# NANO100BN_v1 register map
File version: 1.0
Registers are 32-bit, read-write, reset 0x0 unless marked. A register's access mark holds for its fields unless they carry their own. Offsets are from the block's base; [hi:lo] are bit positions; {n}, {i} and the like mark numbered series; 'fields as' and 'values as' point back to an identical list.

## TMR0 — TMR Register Map
Base 0x40010000
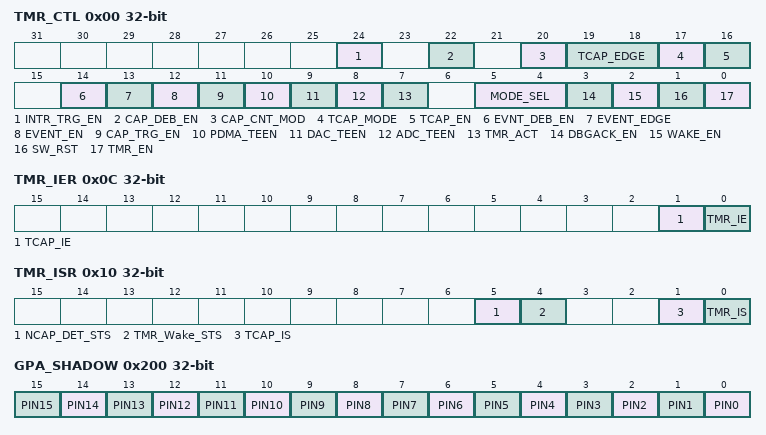
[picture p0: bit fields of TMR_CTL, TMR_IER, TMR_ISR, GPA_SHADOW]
0x00 TMR_CTL — Timer x Control Register
  [24] INTR_TRG_EN — Inter-Timer Trigger Mode Enable. This bit controls if Inter-timer Trigger mode is enabled. If Inter-timer Trigger mode is enabled, the TMRx will be in counter mode and counting with external Clock Source or event. And, TMRx+1 will be in trigger-counting mode of capture function. Note: For TMRx+1_CTL, this bit is ignored and the read back value is always 1'b0.
    0=Inter-timer trigger mode Disabled; 1=Inter-timer trigger mode Enabled
  [22] CAP_DEB_EN — Tcapture Pin De-bounce Enable. When CAP_DEB_EN is set, the Tcapture pin de-bounce circuit will be enabled to eliminate the bouncing of the signal. In de-bounce circuit the Tcapture pin signal will be sampled 4 times by TMRx_CLK. Note: When TCAP_EN is enabled, enable this bit is recommended. And, while TCAP_EN is disabled, disable this bit is recommended to save power consumption.
    0=De-bounce circuit Disabled; 1=De-bounce circuit Enabled
  [20] CAP_CNT_MOD — Timer Capture Counting Mode Selection. This bit indicates the behavior of 24-bit up-counting timer while TCAP_EN is set to high. If this bit is 0, the free-counting mode, the behavior of 24-bit up-counting timer is defined by MODE_SEL field. When TCAP_EN is set, TCAP_MODE is 0, and the transition of Tcapture pin matches the TCAP_EDGE setting, the value of 24-bit up-counting timer will be saved into register TMRx_TCAPn. If this bit is 1, Trigger-counting mode, 24-bit up-counting timer will be not counting and keep its value at zero. When TCAP_EN is set, TCAP_MODE is 0, and once the transition of external pin matches the 1st transition of TCAP_EDGE setting, the 24-bit up-counting timer will start counting. And then if the transition of external pin matches the 2nd transition of TCAP_EDGE setting, the 24-bit up-counting timer will stop counting. And its value will be saved into register TMRx_TCAPn. Note: For TMRx+1_CTL, if INTR_TRG_EN is set, the CAP_CNT_MOD will be forced to high, the capture with Trigger-counting Timer mode.
    0=Capture with free-counting timer mode; 1=Capture with trigger-counting timer mode
  [19:18] TCAP_EDGE — Tcapture Pin Edge Detect Selection
  [17] TCAP_MODE — Tcapture Pin Function Mode Selection. This bit indicates if the transition on Tcapture pin is used as timer counter reset function or timer capture function. Note: For TMRx+1_CTL, if INTR_TRG_EN is set, the TCAP_MODE will be forced to low.
    0=The transition on Tcapture pin is used as timer capture function; 1=The transition on Tcapture pin is used as timer counter reset function
  [16] TCAP_EN — Tcapture Pin Functional Enable. This bit controls if the transition on Tcapture pin could be used as timer counter reset function or timer capture function. Note: For TMRx_CTL, if INTR_TRG_EN is set, the TCAP_EN will be forced to low and the Tcapture pin transition is ignored. Note: For TMRx+1_CTL, if INTR_TRG_EN is set, the TCAP_EN will be forced to high.
    0=The transition on Tcapture pin is ignored; 1=The transition on Tcapture pin will result in the capture or reset of 24-bit timer counter
  [14] EVNT_DEB_EN — External Event De-bounce Enable. When EVNT_DEB_EN is set, the external event pin de-bounce circuit will be enabled to eliminate the bouncing of the signal. In de-bounce circuit the external event pin will be sampled 4 times by TMRx_CLK. Note: When EVENT_EN is enabled, enable this bit is recommended. And, while EVENT_EN is disabled, disable this bit is recommended to save power consumption.
    0=De-bounce circuit Disabled; 1=De-bounce circuit Enabled
  [13] EVENT_EDGE — Event Counting Mode Edge Selection. This bit indicates which edge of external event pin enabling the timer to increase 1.
    0=A falling edge of external event enabling the timer to increase 1; 1=A rising edge of external event enabling the timer to increase 1
  [12] EVENT_EN — Event Counting Mode Enable. When EVENT_EN is set, the increase of 24-bit up-counting timer is controlled by external event pin. While the transition of external event pin matches the definition of EVENT_EDGE, the 24-bit up-counting timer increases by 1. Or, the 24-bit up-counting timer will keep its value unchanged.
    0=Timer counting is not controlled by external event pin; 1=Timer counting is controlled by external event pin
  [11] CAP_TRG_EN — TCAP_IS Trigger Mode Enable. This bit controls if the TMR_IS or TCAP_IS is used to trigger PDMA, DAC and ADC while TMR_IS or TCAP_IS is set. If this bit is low and TMR_IS is set, timer will generate an internal trigger event to PDMA, DAC or ADC while related trigger enable bit (PDMA_TEEN, DAC_TEEN or ADC_TEEN) is also set. If this bit is set high and TCAP_IS is set, timer will generate an internal trigger event to PDMA, DAC or ADC while related trigger enable bit (PDMA_TEEN, DAC_TEEN or ADC_TEEN) is also set.
    0=TMR_IS is used to trigger PDMA, DAC and ADC; 1=TCAP_IS is used to trigger PDMA, DAC and ADC
  [10] PDMA_TEEN — TMR_IS or TCAP_IS Trigger PDMA Enable. This bit controls if TMR_IS or TCAP_IS could trigger PDMA. When PDMA_TEEN is set, TMR_IS is set and the CAP_TRG_EN is low, the timer controller will generate an internal trigger event to PDMA controller. When PDMA_TEEN is set, TCAP_IS is set and the CAP_TRG_EN is high, the timer controller will generate an internal trigger event to PDMA controller.
    0=TMR_IS or TCAP_IS trigger PDMA Disabled; 1=TMR_IS or TCAP_IS trigger PDMA Enabled
  [9] DAC_TEEN — TMR_IS or TCAP_IS Trigger DAC Enable. This bit controls if TMR_IS or TCAP_IS could trigger DAC. When DAC_TEEN is set, TMR_IS is set and the CAP_TRG_EN is low, the timer controller will generate an internal trigger event to DAC controller. When DAC_TEEN is set, TCAP_IS is set and the CAP_TRG_EN is high, the timer controller will generate an internal trigger event to DAC controller.
    0=TMR_IS or TCAP_IS trigger DAC Disabled; 1=TMR_IS or TCAP_IS trigger DAC Enabled
  [8] ADC_TEEN — TMR_IS or TCAP_IS Trigger ADC Enable. This bit controls if TMR_IS or TCAP_IS could trigger ADC. When ADC_TEEN is set, TMR_IS is set and the CAP_TRG_EN is low, the timer controller will generate an internal trigger event to ADC controller. When ADC_TEEN is set, TCAP_IS is set and the CAP_TRG_EN is high, the timer controller will generate an internal trigger event to ADC controller.
    0=TMR_IS or TCAP_IS trigger ADC Disabled; 1=TMR_IS or TCAP_IS trigger ADC Enabled
  [7] TMR_ACT ro — Timer Active Status Bit (Read Only). This bit indicates the timer counter status of timer.
    0=Timer is not active; 1=Timer is in active
  [5:4] MODE_SEL — Timer Operating Mode Select
  [3] DBGACK_EN — ICE Debug Mode Acknowledge Ineffective Enable
    0=ICE debug mode acknowledgement effects TIMER counting and TIMER counter will be held while ICE debug mode acknowledged; 1=ICE debug mode acknowledgement is ineffective and TIMER counter will keep going no matter ICE debug mode acknowledged or not
  [2] WAKE_EN — Wake-up Enable. When WAKE_EN is set and the TMR_IS or TCAP_IS is set, the timer controller will generate a wake-up trigger event to CPU.
    0=Wake-up trigger event Disabled; 1=Wake-up trigger event Enabled
  [1] SW_RST — Software Reset. Set this bit will reset the timer counter, pre-scale counter and also force TMR_CTL [TMR_EN] to 0. Note: This bit will be auto cleared and takes at least 3 TMRx_CLK clock cycles.
    0=No effect; 1=Reset Timer's pre-scale counter, internal 24-bit up-counter and TMR_CTL [TMR_EN] bit
  [0] TMR_EN — Timer Counter Enable Bit
    0=Stops/Suspends counting; 1=Starts counting
0x04 TMR_PRECNT — Timer x Pre-Scale Counter Register
  [7:0] PRESCALE_CNT — Pre-scale Counter
0x08 TMR_CMPR — Timer x Compare Register
  [23:0] TMR_CMP — Timer Compared Value. TMR_CMP is a 24-bit compared register. When the internal 24-bit up-counter counts and its value is equal to TMR_CMP value, a Timer Interrupt is requested if the timer interrupt is enabled with TMR_IER [TMR_IE] is enabled. The TMR_CMP value defines the timer counting cycle time. Note1: Never write 0x0 or 0x1 in TMR_CMP, or the core will run into unknown state. Note2: No matter TMR_CTL [TMR_EN] is 0 or 1, whenever software write a new value into this register, TIMER will restart counting using this new value and abort previous count.
0x0C TMR_IER — Timer x Interrupt Enable Register
  [1] TCAP_IE — Timer Capture Function Interrupt Enable. Note: If timer external pin function interrupt is enabled, the timer asserts its interrupt signal when the TCAP_EN is set and the transition of external pin matches the TCAP_EDGE setting
    0=Timer External Pin Function Interrupt Disabled; 1=Timer External Pin Function Interrupt Enabled
  [0] TMR_IE — Timer Interrupt Enable. Note: If timer interrupt is enabled, the timer asserts its interrupt signal when the associated counter is equal to TMR_CMPR.
    0=Timer Interrupt Disabled; 1=Timer Interrupt Enabled
0x10 TMR_ISR — Timer x Interrupt Status Register
  [5] NCAP_DET_STS — New Capture Detected Status. This status is to indicate there is a new incoming capture event detected before CPU clearing the TCAP_IS status. If the above condition occurred, the Timer will keep register TMRx_CAP unchanged and drop the new capture value. This bit is also cleared to 0 while TCAP_IS is cleared.
    0=New incoming capture event didn't detect before CPU clearing TCAP_IS status; 1=New incoming capture event detected before CPU clearing TCAP_IS status
  [4] TMR_Wake_STS — Timer Wake-up Status. If timer causes CPU wakes up from power-down mode, this bit will be set to high. It must be cleared by software with a write 1 to this bit.
    0=Timer does not cause system wake-up; 1=Wakes system up from power-down mode by Timer timeout
  [1] TCAP_IS — Timer Capture Function Interrupt Status. This bit indicates the external pin function interrupt status of Timer. This bit is set by hardware when TCAP_EN is set high, and the transition of external pin matches the TCAP_EDGE setting. Write 1 to clear this bit to zero. If this bit is active and TCAP_IE is enabled, Timer will trigger an interrupt to CPU.
  [0] TMR_IS — Timer Interrupt Status. This bit indicates the interrupt status of Timer. This bit is set by hardware when the up counting value of internal 24-bit counter matches the timer compared value (TMR_CMPR). Write 1 to clear this bit to 0. If this bit is active and TMR_IE is enabled, Timer will trigger an interrupt to CPU.
0x14 TMR_DR ro — Timer x Data Register
  [23:0] TDR — Timer Data Register. User can read this register for internal 24-bit timer up-counter value.
0x18 TMR_TCAP ro — Timer x Capture Data Register
  [23:0] CAP — Timer Capture Data Register. When TCAP_EN is set, TCAP_MODE is 0, and the transition of external pin matches the TCAP_EDGE setting, the value of 24-bit up-counting timer will be saved into register TMRx_TCAP. User can read this register for the counter value.
0x200 GPA_SHADOW ro (reset mask 0xFFFF0000) — GPIO Port A Pin Value Shadow Register
  [n] PIN{n} (n=0..15) — GPIO Port [A/B/C/D/E/F] Pin Values. The value read from each of these bit reflects the actual status of the respective GPI/O pin. These registers are shadow registers of GPIOx_PIN register. Note: For GPF_SHADOW, bits [15:9] are reserved.
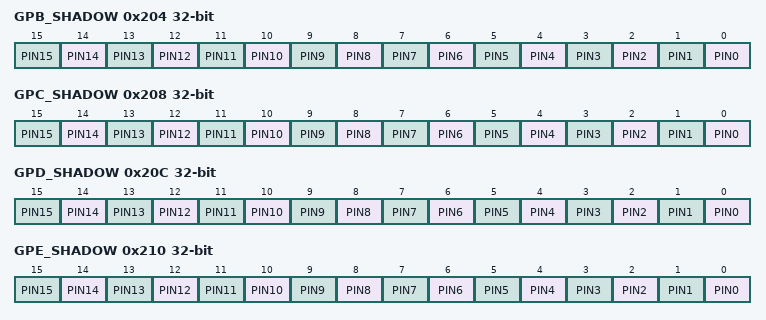
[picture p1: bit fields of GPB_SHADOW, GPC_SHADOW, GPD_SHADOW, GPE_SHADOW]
0x204 GPB_SHADOW ro (reset mask 0xFFFF0000) — GPIO Port B Pin Value Shadow Register
  fields as GPA_SHADOW
0x208 GPC_SHADOW ro (reset mask 0xFFFF0000) — GPIO Port C Pin Value Shadow Register
  fields as GPA_SHADOW
0x20C GPD_SHADOW ro (reset mask 0xFFFF0000) — GPIO Port D Pin Value Shadow Register
  fields as GPA_SHADOW
0x210 GPE_SHADOW ro (reset mask 0xFFFF0000) — GPIO Port E Pin Value Shadow Register
  fields as GPA_SHADOW
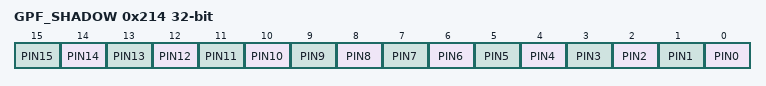
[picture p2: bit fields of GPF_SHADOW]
0x214 GPF_SHADOW ro (reset mask 0xFFFF0000) — GPIO Port F Pin Value Shadow Register
  fields as GPA_SHADOW

## TMR1 — TMR Register Map
Base 0x40010100
Registers as TMR0, without GPA_SHADOW, GPB_SHADOW, GPC_SHADOW, GPD_SHADOW, GPE_SHADOW, GPF_SHADOW.

## TMR2 — TMR Register Map
Base 0x40110000
Registers as TMR0, without GPA_SHADOW, GPB_SHADOW, GPC_SHADOW, GPD_SHADOW, GPE_SHADOW, GPF_SHADOW.

## TMR3 — TMR Register Map
Base 0x40110100
Registers as TMR0, without GPA_SHADOW, GPB_SHADOW, GPC_SHADOW, GPD_SHADOW, GPE_SHADOW, GPF_SHADOW.
